VERSION ""

NS_ :

BS_:

BU_: SZL XXX

BO_ 200 NEW_MSG_1: 6 SZL

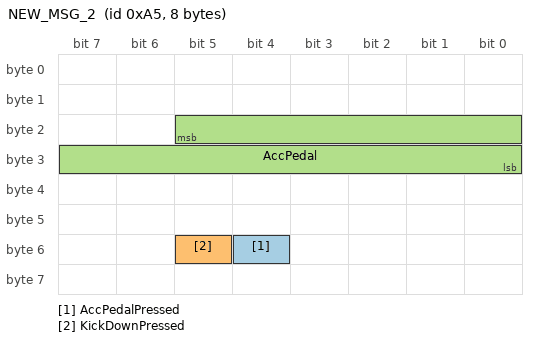
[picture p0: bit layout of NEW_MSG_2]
BO_ 165 NEW_MSG_2: 8 JBE
 SG_ AccPedalPressed : 52|1@0+ (1,0) [0|7] "" XXX
 SG_ KickDownPressed : 53|1@0+ (1,0) [0|3] "" XXX
 SG_ AccPedal : 21|14@0+ (0.00952925481,-36.5923384704) [0|100] "%" XXX

BO_ 168 Brake: 8 XXX
 SG_ Brake pedal depressed #2 : 62|1@0+ (1,0) [0|1] "" XXX
 SG_ Brake pedal depressed #1 : 61|1@0+ (1,0) [0|1] "" XXX

CM_ SG_ 168 Brake pedal depressed #2 "Brake depressed when driver presses the brake";
CM_ SG_ 168 Brake pedal depressed #1 "Brake depressed when driver presses the brake";
